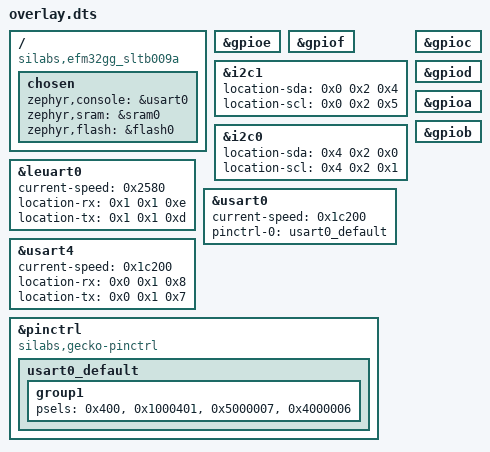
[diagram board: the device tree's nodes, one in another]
/ {
	compatible = "silabs,efm32gg_sltb009a";
	chosen {
		zephyr,console = &usart0;
		zephyr,sram = &sram0;
		zephyr,flash = &flash0;
	};
};
&gpioe{
	status = "okay";
};
&gpiof{
	status = "okay";
};
&i2c1{
	status = "okay";
	location-sda = < 0x0 0x2 0x4 >;
	location-scl = < 0x0 0x2 0x5 >;
};
&i2c0{
	status = "okay";
	location-sda = < 0x4 0x2 0x0 >;
	location-scl = < 0x4 0x2 0x1 >;
};
&leuart0{
	status = "okay";
	current-speed = < 0x2580 >;
	location-rx = < 0x1 0x1 0xe >;
	location-tx = < 0x1 0x1 0xd >;
};
&gpioc{
	status = "okay";
};
&usart0{
	status = "okay";
	current-speed = < 0x1c200 >;
	pinctrl-0 = < &usart0_default >;
	pinctrl-names = "default";
};
&gpiod{
	status = "okay";
};
&gpioa{
	status = "okay";
};
&gpiob{
	status = "okay";
};
&usart4{
	status = "okay";
	current-speed = < 0x1c200 >;
	location-rx = < 0x0 0x1 0x8 >;
	location-tx = < 0x0 0x1 0x7 >;
};
&pinctrl{
	compatible = "silabs,gecko-pinctrl";
	usart0_default: usart0_default {
		group1 {
			psels = < 0x400 >, < 0x1000401 >, < 0x5000007 >, < 0x4000006 >;
		};
	};
};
